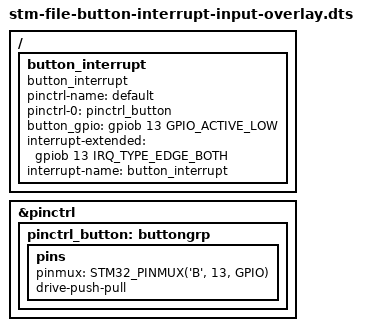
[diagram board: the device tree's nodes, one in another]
/dts-v1/;
/plugin/;

#include <dt-bindings/pinctrl/stm32-pinfunc.h>
#include <dt-bindings/input/input.h>
#include <dt-bindings/mfd/st,stpmic1.h>
#include <dt-bindings/gpio/gpio.h>
#include <dt-bindings/interrupt-controller/irq.h>

/ {
    fragment@0 {
        target-path = "/";
        __overlay__ {
            button_interrupt {
                compatible = "button_interrupt";
                pinctrl-name = "default";
                pinctrl-0 = <&pinctrl_button>;
                button_gpio = <&gpiob 13 GPIO_ACTIVE_LOW>; // 默认把gpio引脚设置成低电平
                status = "okay";
                interrupt-extended = <&gpiob 13 IRQ_TYPE_EDGE_BOTH>;
                interrupt-name = "button_interrupt";
            };
        };
    };

    fragment@1 {
        target = <&pinctrl>;
        __overlay__ {
            pinctrl_button: buttongrp {
                pins {
                    pinmux = <STM32_PINMUX('B', 13, GPIO)>;
                    drive-push-pull;
                };
            };
        };
    };
};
